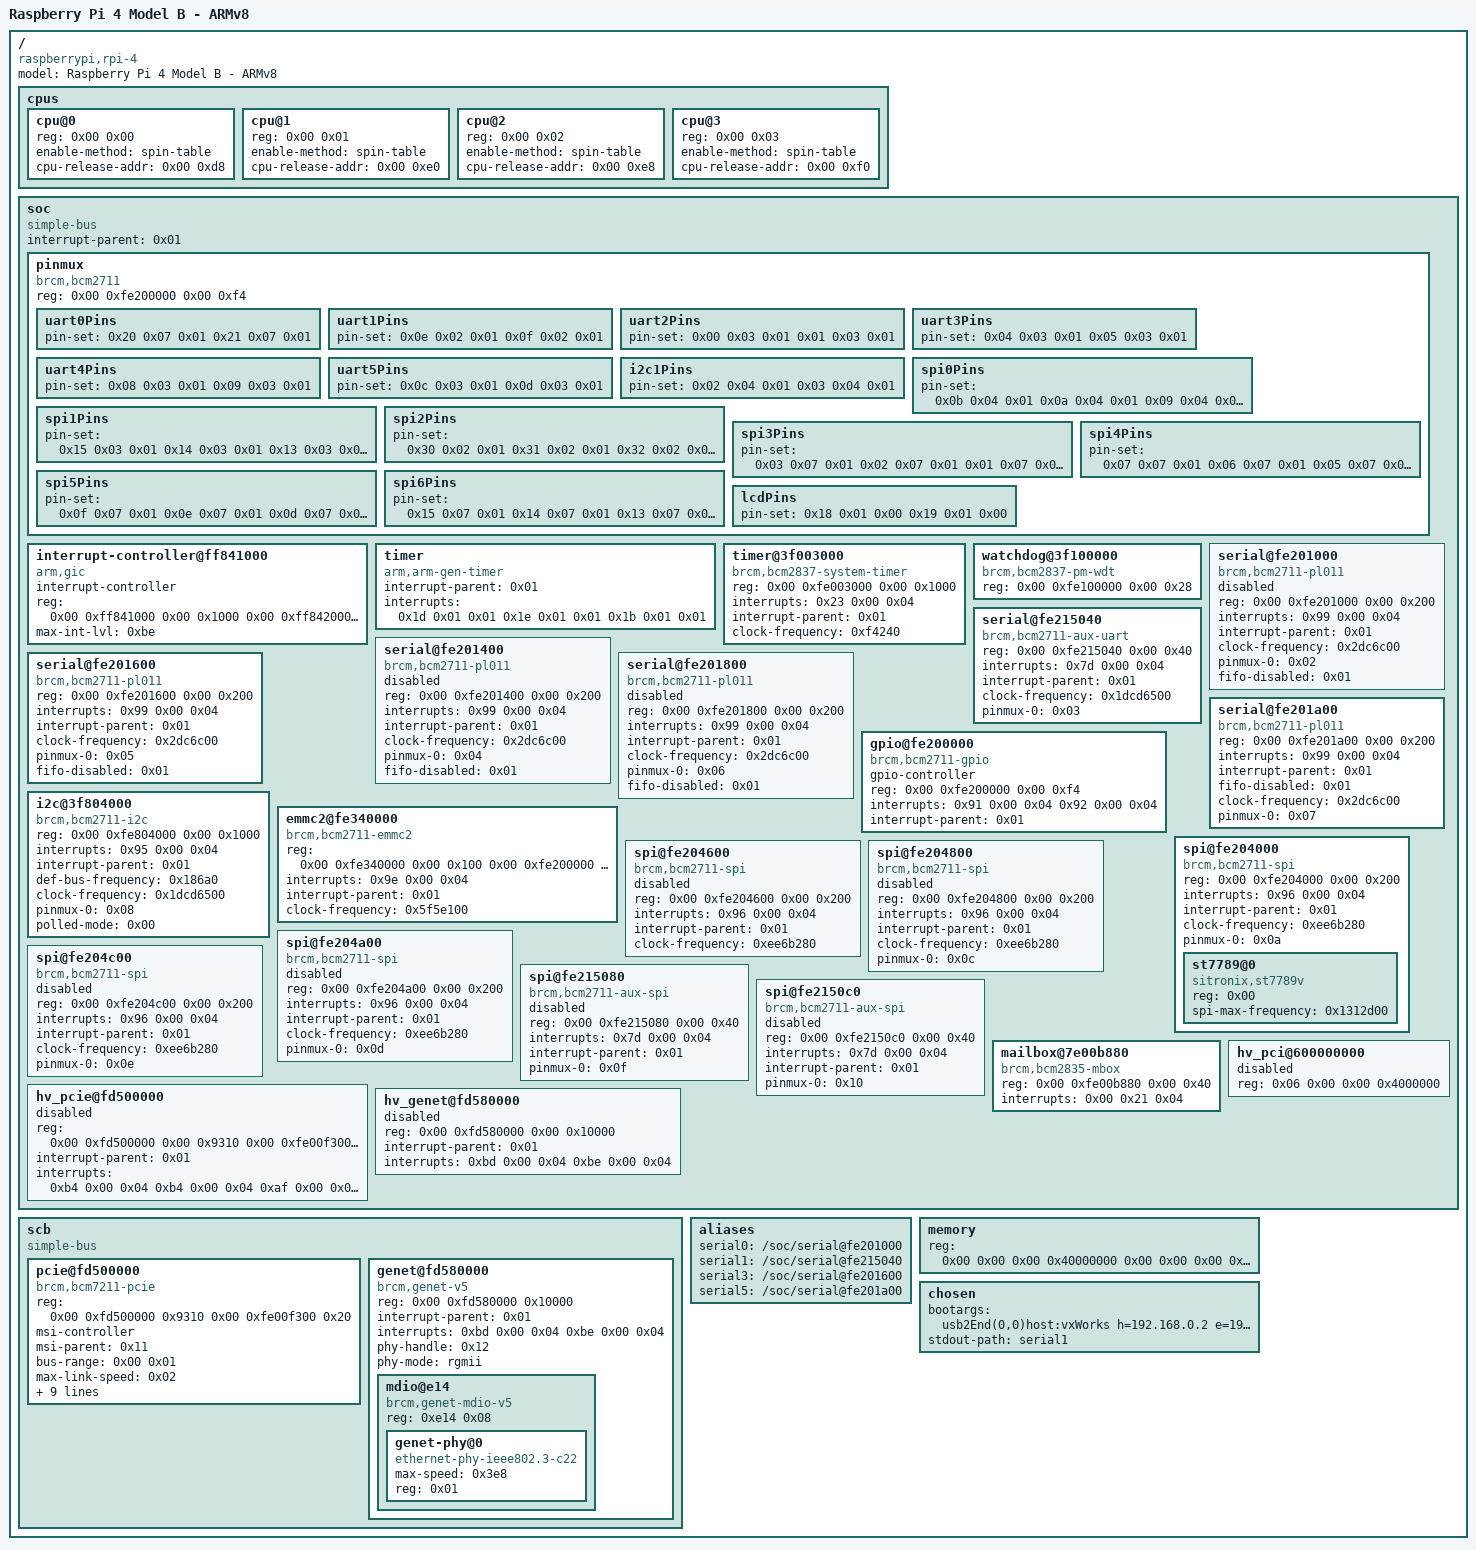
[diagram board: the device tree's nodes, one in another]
/dts-v1/;

/ {
	compatible = "raspberrypi,rpi-4";
	#address-cells = <0x02>;
	#size-cells = <0x02>;
	model = "Raspberry Pi 4 Model B - ARMv8";

	cpus {
		#size-cells = <0x00>;
		#address-cells = <0x02>;

		cpu@0 {
			device_type = "cpu";
			reg = <0x00 0x00>;
			enable-method = "spin-table";
			cpu-release-addr = <0x00 0xd8>;
		};

		cpu@1 {
			device_type = "cpu";
			reg = <0x00 0x01>;
			enable-method = "spin-table";
			cpu-release-addr = <0x00 0xe0>;
		};

		cpu@2 {
			device_type = "cpu";
			reg = <0x00 0x02>;
			enable-method = "spin-table";
			cpu-release-addr = <0x00 0xe8>;
		};

		cpu@3 {
			device_type = "cpu";
			reg = <0x00 0x03>;
			enable-method = "spin-table";
			cpu-release-addr = <0x00 0xf0>;
		};
	};

	soc {
		compatible = "simple-bus";
		device_type = "soc";
		#address-cells = <0x02>;
		#size-cells = <0x02>;
		interrupt-parent = <0x01>;

		pinmux {
			compatible = "brcm,bcm2711";
			reg = <0x00 0xfe200000 0x00 0xf4>;

			uart0Pins {
				pin-set = <0x20 0x07 0x01 0x21 0x07 0x01>;
				phandle = <0x02>;
			};

			uart1Pins {
				pin-set = <0x0e 0x02 0x01 0x0f 0x02 0x01>;
				phandle = <0x03>;
			};

			uart2Pins {
				pin-set = <0x00 0x03 0x01 0x01 0x03 0x01>;
				phandle = <0x04>;
			};

			uart3Pins {
				pin-set = <0x04 0x03 0x01 0x05 0x03 0x01>;
				phandle = <0x05>;
			};

			uart4Pins {
				pin-set = <0x08 0x03 0x01 0x09 0x03 0x01>;
				phandle = <0x06>;
			};

			uart5Pins {
				pin-set = <0x0c 0x03 0x01 0x0d 0x03 0x01>;
				phandle = <0x07>;
			};

			i2c1Pins {
				pin-set = <0x02 0x04 0x01 0x03 0x04 0x01>;
				phandle = <0x08>;
			};

			spi0Pins {
				pin-set = <0x0b 0x04 0x01 0x0a 0x04 0x01 0x09 0x04 0x01 0x08 0x04 0x01 0x07 0x04 0x01>;
				phandle = <0x0a>;
			};

			spi1Pins {
				pin-set = <0x15 0x03 0x01 0x14 0x03 0x01 0x13 0x03 0x01 0x12 0x03 0x01 0x11 0x03 0x01>;
				phandle = <0x0f>;
			};

			spi2Pins {
				pin-set = <0x30 0x02 0x01 0x31 0x02 0x01 0x32 0x02 0x01 0x2f 0x02 0x01 0x2e 0x02 0x01>;
				phandle = <0x10>;
			};

			spi3Pins {
				pin-set = <0x03 0x07 0x01 0x02 0x07 0x01 0x01 0x07 0x01 0x00 0x07 0x01 0x18 0x02 0x01>;
			};

			spi4Pins {
				pin-set = <0x07 0x07 0x01 0x06 0x07 0x01 0x05 0x07 0x01 0x04 0x07 0x01 0x19 0x07 0x01>;
				phandle = <0x0c>;
			};

			spi5Pins {
				pin-set = <0x0f 0x07 0x01 0x0e 0x07 0x01 0x0d 0x07 0x01 0x0c 0x07 0x01 0x1a 0x02 0x01>;
				phandle = <0x0d>;
			};

			spi6Pins {
				pin-set = <0x15 0x07 0x01 0x14 0x07 0x01 0x13 0x07 0x01 0x12 0x07 0x01 0x1b 0x02 0x01>;
				phandle = <0x0e>;
			};

			lcdPins {
				pin-set = <0x18 0x01 0x00 0x19 0x01 0x00>;
				phandle = <0x0b>;
			};
		};

		interrupt-controller@ff841000 {
			compatible = "arm,gic";
			interrupt-controller;
			#interrupt-cells = <0x03>;
			reg = <0x00 0xff841000 0x00 0x1000 0x00 0xff842000 0x00 0x2000 0x00 0xff844000 0x00 0x2000 0x00 0xff846000 0x00 0x2000>;
			max-int-lvl = <0xbe>;
			phandle = <0x01>;
		};

		timer {
			compatible = "arm,arm-gen-timer";
			interrupt-parent = <0x01>;
			interrupts = <0x1d 0x01 0x01 0x1e 0x01 0x01 0x1b 0x01 0x01>;
		};

		timer@3f003000 {
			compatible = "brcm,bcm2837-system-timer", "brcm,bcm2835-system-timer";
			reg = <0x00 0xfe003000 0x00 0x1000>;
			interrupts = <0x23 0x00 0x04>;
			interrupt-parent = <0x01>;
			clock-frequency = <0xf4240>;
		};

		watchdog@3f100000 {
			compatible = "brcm,bcm2837-pm-wdt";
			reg = <0x00 0xfe100000 0x00 0x28>;
			status = "okay";
		};

		serial@fe201000 {
			compatible = "brcm,bcm2711-pl011", "arm,pl011", "arm,primecell";
			reg = <0x00 0xfe201000 0x00 0x200>;
			interrupts = <0x99 0x00 0x04>;
			interrupt-parent = <0x01>;
			clock-frequency = <0x2dc6c00>;
			pinmux-0 = <0x02>;
			fifo-disabled = <0x01>;
			status = "disabled";
		};

		serial@fe215040 {
			compatible = "brcm,bcm2711-aux-uart";
			reg = <0x00 0xfe215040 0x00 0x40>;
			interrupts = <0x7d 0x00 0x04>;
			interrupt-parent = <0x01>;
			clock-frequency = <0x1dcd6500>;
			pinmux-0 = <0x03>;
			status = "okay";
		};

		serial@fe201400 {
			compatible = "brcm,bcm2711-pl011", "arm,pl011", "arm,primecell";
			reg = <0x00 0xfe201400 0x00 0x200>;
			interrupts = <0x99 0x00 0x04>;
			interrupt-parent = <0x01>;
			clock-frequency = <0x2dc6c00>;
			pinmux-0 = <0x04>;
			fifo-disabled = <0x01>;
			status = "disabled";
		};

		serial@fe201600 {
			compatible = "brcm,bcm2711-pl011", "arm,pl011", "arm,primecell";
			reg = <0x00 0xfe201600 0x00 0x200>;
			interrupts = <0x99 0x00 0x04>;
			interrupt-parent = <0x01>;
			clock-frequency = <0x2dc6c00>;
			pinmux-0 = <0x05>;
			fifo-disabled = <0x01>;
			status = "okay";
		};

		serial@fe201800 {
			compatible = "brcm,bcm2711-pl011", "arm,pl011", "arm,primecell";
			reg = <0x00 0xfe201800 0x00 0x200>;
			interrupts = <0x99 0x00 0x04>;
			interrupt-parent = <0x01>;
			clock-frequency = <0x2dc6c00>;
			pinmux-0 = <0x06>;
			fifo-disabled = <0x01>;
			status = "disabled";
		};

		serial@fe201a00 {
			compatible = "brcm,bcm2711-pl011", "arm,pl011", "arm,primecell";
			reg = <0x00 0xfe201a00 0x00 0x200>;
			interrupts = <0x99 0x00 0x04>;
			interrupt-parent = <0x01>;
			fifo-disabled = <0x01>;
			clock-frequency = <0x2dc6c00>;
			pinmux-0 = <0x07>;
			status = "okay";
		};

		gpio@fe200000 {
			compatible = "brcm,bcm2711-gpio";
			gpio-controller;
			#gpio-cells = <0x04>;
			reg = <0x00 0xfe200000 0x00 0xf4>;
			interrupts = <0x91 0x00 0x04 0x92 0x00 0x04>;
			interrupt-parent = <0x01>;
			status = "okay";
			phandle = <0x09>;
		};

		i2c@3f804000 {
			compatible = "brcm,bcm2711-i2c";
			reg = <0x00 0xfe804000 0x00 0x1000>;
			interrupts = <0x95 0x00 0x04>;
			interrupt-parent = <0x01>;
			def-bus-frequency = <0x186a0>;
			clock-frequency = <0x1dcd6500>;
			pinmux-0 = <0x08>;
			#address-cells = <0x01>;
			#size-cells = <0x00>;
			polled-mode = <0x00>;
			status = "okay";

		};

		emmc2@fe340000 {
			compatible = "brcm,bcm2711-emmc2";
			reg = <0x00 0xfe340000 0x00 0x100 0x00 0xfe200000 0x00 0xf4>;
			interrupts = <0x9e 0x00 0x04>;
			interrupt-parent = <0x01>;
			clock-frequency = <0x5f5e100>;
			status = "okay";
		};

		spi@fe204000 {
			compatible = "brcm,bcm2711-spi";
			#address-cells = <0x01>;
			#size-cells = <0x00>;
			reg = <0x00 0xfe204000 0x00 0x200>;
			interrupts = <0x96 0x00 0x04>;
			interrupt-parent = <0x01>;
			clock-frequency = <0xee6b280>;
			pinmux-0 = <0x0a>;
			status = "okay";

			st7789@0 {
				compatible = "sitronix,st7789v";
				reg = <0x00>;
				spi-max-frequency = <0x1312d00>;
			};
		};

		spi@fe204600 {
			compatible = "brcm,bcm2711-spi";
			#address-cells = <0x01>;
			#size-cells = <0x00>;
			reg = <0x00 0xfe204600 0x00 0x200>;
			interrupts = <0x96 0x00 0x04>;
			interrupt-parent = <0x01>;
			clock-frequency = <0xee6b280>;
			status = "disabled";
		};

		spi@fe204800 {
			compatible = "brcm,bcm2711-spi";
			#address-cells = <0x01>;
			#size-cells = <0x00>;
			reg = <0x00 0xfe204800 0x00 0x200>;
			interrupts = <0x96 0x00 0x04>;
			interrupt-parent = <0x01>;
			clock-frequency = <0xee6b280>;
			pinmux-0 = <0x0c>;
			status = "disabled";
		};

		spi@fe204a00 {
			compatible = "brcm,bcm2711-spi";
			#address-cells = <0x01>;
			#size-cells = <0x00>;
			reg = <0x00 0xfe204a00 0x00 0x200>;
			interrupts = <0x96 0x00 0x04>;
			interrupt-parent = <0x01>;
			clock-frequency = <0xee6b280>;
			pinmux-0 = <0x0d>;
			status = "disabled";
		};

		spi@fe204c00 {
			compatible = "brcm,bcm2711-spi";
			#address-cells = <0x01>;
			#size-cells = <0x00>;
			reg = <0x00 0xfe204c00 0x00 0x200>;
			interrupts = <0x96 0x00 0x04>;
			interrupt-parent = <0x01>;
			clock-frequency = <0xee6b280>;
			pinmux-0 = <0x0e>;
			status = "disabled";
		};

		spi@fe215080 {
			compatible = "brcm,bcm2711-aux-spi";
			#address-cells = <0x01>;
			#size-cells = <0x00>;
			reg = <0x00 0xfe215080 0x00 0x40>;
			interrupts = <0x7d 0x00 0x04>;
			interrupt-parent = <0x01>;
			pinmux-0 = <0x0f>;
			status = "disabled";
		};

		spi@fe2150c0 {
			compatible = "brcm,bcm2711-aux-spi";
			#address-cells = <0x01>;
			#size-cells = <0x00>;
			reg = <0x00 0xfe2150c0 0x00 0x40>;
			interrupts = <0x7d 0x00 0x04>;
			interrupt-parent = <0x01>;
			pinmux-0 = <0x10>;
			status = "disabled";
		};

		mailbox@7e00b880 {
			compatible = "brcm,bcm2835-mbox";
			reg = <0x00 0xfe00b880 0x00 0x40>;
			interrupts = <0x00 0x21 0x04>;
		};

		hv_pcie@fd500000 {
			reg = <0x00 0xfd500000 0x00 0x9310 0x00 0xfe00f300 0x00 0x20>;
			interrupt-parent = <0x01>;
			interrupts = <0xb4 0x00 0x04 0xb4 0x00 0x04 0xaf 0x00 0x04 0xb0 0x00 0x04 0xb1 0x00 0x04 0xb2 0x00 0x04>;
			status = "disabled";
		};

		hv_genet@fd580000 {
			reg = <0x00 0xfd580000 0x00 0x10000>;
			interrupt-parent = <0x01>;
			interrupts = <0xbd 0x00 0x04 0xbe 0x00 0x04>;
			status = "disabled";
		};

		hv_pci@600000000 {
			reg = <0x06 0x00 0x00 0x4000000>;
			status = "disabled";
		};
	};

	scb {
		compatible = "simple-bus";
		#address-cells = <0x02>;
		#size-cells = <0x01>;

		pcie@fd500000 {
			reg = <0x00 0xfd500000 0x9310 0x00 0xfe00f300 0x20>;
			msi-controller;
			msi-parent = <0x11>;
			#address-cells = <0x03>;
			#interrupt-cells = <0x01>;
			#size-cells = <0x02>;
			bus-range = <0x00 0x01>;
			compatible = "brcm,bcm7211-pcie", "brcm,bcm7445-pcie", "brcm,pci-plat-dev";
			max-link-speed = <0x02>;
			tot-num-pcie = <0x01>;
			linux,pci-domain = <0x00>;
			interrupt-parent = <0x01>;
			interrupts = <0xb4 0x00 0x04 0xb4 0x00 0x04>;
			interrupt-names = "pcie", "msi";
			interrupt-map-mask = <0x00 0x00 0x00 0x07>;
			interrupt-map = <0x00 0x00 0x00 0x01 0x01 0xaf 0x00 0x04 0x00 0x00 0x00 0x02 0x01 0xb0 0x00 0x04 0x00 0x00 0x00 0x03 0x01 0xb1 0x00 0x04 0x00 0x00 0x00 0x04 0x01 0xb2 0x00 0x04>;
			ranges = <0x2000000 0x00 0xf8000000 0x06 0x00 0x00 0x4000000>;
			dma-ranges = <0x2000000 0x00 0x00 0x00 0x00 0x01 0x00>;
			status = "okay";
			phandle = <0x11>;
		};

		genet@fd580000 {
			compatible = "brcm,genet-v5";
			reg = <0x00 0xfd580000 0x10000>;
			status = "okay";
			#address-cells = <0x01>;
			#size-cells = <0x01>;
			interrupt-parent = <0x01>;
			interrupts = <0xbd 0x00 0x04 0xbe 0x00 0x04>;
			phy-handle = <0x12>;
			phy-mode = "rgmii";

			mdio@e14 {
				#address-cells = <0x00>;
				#size-cells = <0x01>;
				compatible = "brcm,genet-mdio-v5";
				reg = <0xe14 0x08>;
				reg-names = "mdio";

				genet-phy@0 {
					compatible = "ethernet-phy-ieee802.3-c22";
					max-speed = <0x3e8>;
					reg = <0x01>;
					phandle = <0x12>;
				};
			};
		};
	};

	aliases {
		serial0 = "/soc/serial@fe201000";
		serial1 = "/soc/serial@fe215040";
		serial3 = "/soc/serial@fe201600";
		serial5 = "/soc/serial@fe201a00";
	};

	memory {
		device_type = "memory";
		reg = <0x00 0x00 0x00 0x40000000 0x00 0x00 0x00 0x00 0x00 0x00 0x00 0x00>;
	};

	chosen {
		bootargs = "usb2End(0,0)host:vxWorks h=192.168.0.2 e=192.168.0.3:ffffff00 g=192.168.0.1 u=target pw=vxTarget o=genet0 f=0x40";
		stdout-path = "serial1";
	};
};
